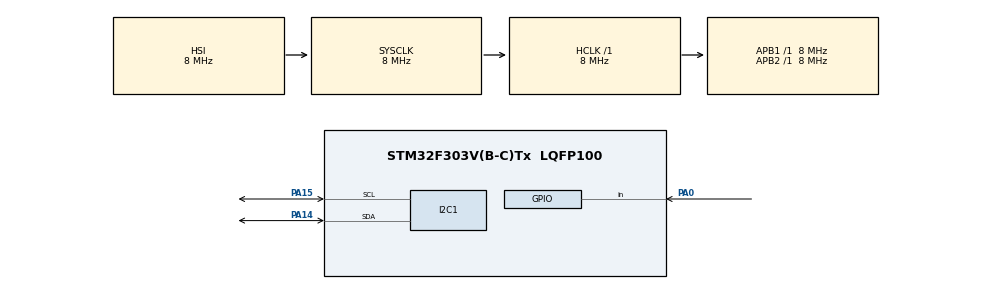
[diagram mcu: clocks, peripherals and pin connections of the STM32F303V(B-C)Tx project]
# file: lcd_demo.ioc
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Dma.I2C1_RX.1.Direction=DMA_PERIPH_TO_MEMORY
Dma.I2C1_RX.1.Instance=DMA1_Channel7
Dma.I2C1_RX.1.MemDataAlignment=DMA_MDATAALIGN_BYTE
Dma.I2C1_RX.1.MemInc=DMA_MINC_ENABLE
Dma.I2C1_RX.1.Mode=DMA_NORMAL
Dma.I2C1_RX.1.PeriphDataAlignment=DMA_PDATAALIGN_BYTE
Dma.I2C1_RX.1.PeriphInc=DMA_PINC_DISABLE
Dma.I2C1_RX.1.Priority=DMA_PRIORITY_LOW
Dma.I2C1_TX.0.Direction=DMA_MEMORY_TO_PERIPH
Dma.I2C1_TX.0.Instance=DMA1_Channel6
Dma.I2C1_TX.0.MemDataAlignment=DMA_MDATAALIGN_BYTE
Dma.I2C1_TX.0.MemInc=DMA_MINC_ENABLE
Dma.I2C1_TX.0.Mode=DMA_NORMAL
Dma.I2C1_TX.0.PeriphDataAlignment=DMA_PDATAALIGN_BYTE
Dma.I2C1_TX.0.PeriphInc=DMA_PINC_DISABLE
Dma.I2C1_TX.0.Priority=DMA_PRIORITY_LOW
Dma.Request0=I2C1_TX
Dma.Request1=I2C1_RX
FREERTOS.INCLUDE_vTaskDelayUntil=1
FREERTOS.Tasks01=defaultTask,0,128,StartDefaultTask,Default,NULL,Dynamic,NULL,NULL
Mcu.Family=STM32F3
Mcu.Name=STM32F303V(B-C)Tx
Mcu.Package=LQFP100
NVIC.DMA1_Channel6_IRQn=true\:5\:0\:false\:false\:true\:true\:false\:true
NVIC.DMA1_Channel7_IRQn=true\:5\:0\:false\:false\:true\:true\:false\:true
NVIC.I2C1_ER_IRQn=true\:5\:0\:false\:false\:true\:true\:true\:true
NVIC.I2C1_EV_IRQn=true\:5\:0\:false\:false\:true\:true\:true\:true
NVIC.PriorityGroup=NVIC_PRIORITYGROUP_4
PA0.Signal=GPIO_Input
PA14.Mode=I2C
PA14.Signal=I2C1_SDA
PA15.Mode=I2C
PA15.Signal=I2C1_SCL
ProjectManager.HeapSize=0x200
ProjectManager.StackSize=0x400
ProjectManager.TargetToolchain=STM32CubeIDE
RCC.AHBFreq_Value=8000000
RCC.APB1Freq_Value=8000000
RCC.APB2Freq_Value=8000000
RCC.CortexFreq_Value=8000000
RCC.HSE_VALUE=8000000
RCC.HSI_VALUE=8000000
RCC.LSE_VALUE=32768
RCC.SYSCLKFreq_VALUE=8000000
VP_FREERTOS_VS_CMSIS_V1.Mode=CMSIS_V1
board=custom

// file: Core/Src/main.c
/* USER CODE BEGIN Header */
/**
  ******************************************************************************
  * @file           : main.c
  * @brief          : Main program body
  ******************************************************************************
  * @attention
  *
  * Copyright (c) 2022 STMicroelectronics.
  * All rights reserved.
  *
  * This software is licensed under terms that can be found in the LICENSE file
  * in the root directory of this software component.
  * If no LICENSE file comes with this software, it is provided AS-IS.
  *
  ******************************************************************************
  */
/* USER CODE END Header */
#include "main.h"
#include "cmsis_os.h"

/* USER CODE BEGIN Includes */
#include "lcd_hd44780_i2c.h"
#include <stdio.h>
#include <string.h>
/* USER CODE END Includes */

I2C_HandleTypeDef hi2c1;
DMA_HandleTypeDef hdma_i2c1_tx;
DMA_HandleTypeDef hdma_i2c1_rx;

osThreadId defaultTaskHandle;

void SystemClock_Config(void);
static void MX_GPIO_Init(void);
static void MX_I2C1_Init(void);
static void MX_DMA_Init(void);
void StartDefaultTask(void const * argument);

int main(void)
{
  /* USER CODE BEGIN 1 */
	lcdInit(&hi2c1, 0x4E, 2, 16);       			      // init lcd (i2c reference, LCD address, lines, rows)
	lcdAutoscrollOff();								              // turn off autoscroll
	lcdBacklightOn();								                // turn on backlight
	lcdDisplayClear();                  			      // clear the screen

  /* USER CODE END 1 */

  /* MCU Configuration--------------------------------------------------------*/

  /* Reset of all peripherals, Initializes the Flash interface and the Systick. */
  HAL_Init();

  /* Configure the system clock */
  SystemClock_Config();

  /* Initialize all configured peripherals */
  MX_GPIO_Init();
  MX_I2C1_Init();
  MX_DMA_Init();

  /* Create the thread(s) */
  /* definition and creation of defaultTask */
  osThreadDef(defaultTask, StartDefaultTask, osPriorityNormal, 0, 128);
  defaultTaskHandle = osThreadCreate(osThread(defaultTask), NULL);

  /* Start scheduler */
  osKernelStart();

  /* We should never get here as control is now taken by the scheduler */
  /* Infinite loop */
  /* USER CODE BEGIN WHILE */
  while (1)
  {
    /* USER CODE END WHILE*/
	lcdSetCursorPosition(2, 0);         			      // set the cursor
	lcdPrintStr((uint8_t*)"welcome AERO!", 13);   	// print
	lcdSetCursorPosition(2, 1);         			      // next line
	lcdPrintStr((uint8_t*)"booting up...", 13);   	// print

	HAL_Delay(3000);
	lcdDisplayClear();

  }
}

void SystemClock_Config(void)
{
  RCC_OscInitTypeDef RCC_OscInitStruct = {0};
  RCC_ClkInitTypeDef RCC_ClkInitStruct = {0};
  RCC_PeriphCLKInitTypeDef PeriphClkInit = {0};

  /** Initializes the RCC Oscillators according to the specified parameters
  * in the RCC_OscInitTypeDef structure.
  */
  RCC_OscInitStruct.OscillatorType = RCC_OSCILLATORTYPE_HSI;
  RCC_OscInitStruct.HSIState = RCC_HSI_ON;
  RCC_OscInitStruct.HSICalibrationValue = RCC_HSICALIBRATION_DEFAULT;
  RCC_OscInitStruct.PLL.PLLState = RCC_PLL_NONE;
  if (HAL_RCC_OscConfig(&RCC_OscInitStruct) != HAL_OK)
  {
    Error_Handler();
  }
  /** Initializes the CPU, AHB and APB buses clocks
  */
  RCC_ClkInitStruct.ClockType = RCC_CLOCKTYPE_HCLK|RCC_CLOCKTYPE_SYSCLK
                              |RCC_CLOCKTYPE_PCLK1|RCC_CLOCKTYPE_PCLK2;
  RCC_ClkInitStruct.SYSCLKSource = RCC_SYSCLKSOURCE_HSI;
  RCC_ClkInitStruct.AHBCLKDivider = RCC_SYSCLK_DIV1;
  RCC_ClkInitStruct.APB1CLKDivider = RCC_HCLK_DIV1;
  RCC_ClkInitStruct.APB2CLKDivider = RCC_HCLK_DIV1;

  if (HAL_RCC_ClockConfig(&RCC_ClkInitStruct, FLASH_LATENCY_0) != HAL_OK)
  {
    Error_Handler();
  }
  PeriphClkInit.PeriphClockSelection = RCC_PERIPHCLK_I2C1;
  PeriphClkInit.I2c1ClockSelection = RCC_I2C1CLKSOURCE_HSI;
  if (HAL_RCCEx_PeriphCLKConfig(&PeriphClkInit) != HAL_OK)
  {
    Error_Handler();
  }
}

static void MX_I2C1_Init(void)
{

  hi2c1.Instance = I2C1;
  hi2c1.Init.Timing = 0x2000090E;
  hi2c1.Init.OwnAddress1 = 0;
  hi2c1.Init.AddressingMode = I2C_ADDRESSINGMODE_7BIT;
  hi2c1.Init.DualAddressMode = I2C_DUALADDRESS_DISABLE;
  hi2c1.Init.OwnAddress2 = 0;
  hi2c1.Init.OwnAddress2Masks = I2C_OA2_NOMASK;
  hi2c1.Init.GeneralCallMode = I2C_GENERALCALL_DISABLE;
  hi2c1.Init.NoStretchMode = I2C_NOSTRETCH_DISABLE;
  if (HAL_I2C_Init(&hi2c1) != HAL_OK)
  {
    Error_Handler();
  }
  /** Configure Analogue filter
  */
  if (HAL_I2CEx_ConfigAnalogFilter(&hi2c1, I2C_ANALOGFILTER_ENABLE) != HAL_OK)
  {
    Error_Handler();
  }
  /** Configure Digital filter
  */
  if (HAL_I2CEx_ConfigDigitalFilter(&hi2c1, 0) != HAL_OK)
  {
    Error_Handler();
  }

}

static void MX_DMA_Init(void)
{

  /* DMA controller clock enable */
  __HAL_RCC_DMA1_CLK_ENABLE();

  /* DMA interrupt init */
  /* DMA1_Channel6_IRQn interrupt configuration */
  HAL_NVIC_SetPriority(DMA1_Channel6_IRQn, 5, 0);
  HAL_NVIC_EnableIRQ(DMA1_Channel6_IRQn);
  /* DMA1_Channel7_IRQn interrupt configuration */
  HAL_NVIC_SetPriority(DMA1_Channel7_IRQn, 5, 0);
  HAL_NVIC_EnableIRQ(DMA1_Channel7_IRQn);

}

static void MX_GPIO_Init(void)
{
  GPIO_InitTypeDef GPIO_InitStruct = {0};

  /* GPIO Ports Clock Enable */
  __HAL_RCC_GPIOA_CLK_ENABLE();

  /*Configure GPIO pin : PA0 */
  GPIO_InitStruct.Pin = GPIO_PIN_0;
  GPIO_InitStruct.Mode = GPIO_MODE_INPUT;
  GPIO_InitStruct.Pull = GPIO_NOPULL;
  HAL_GPIO_Init(GPIOA, &GPIO_InitStruct);

}

void StartDefaultTask(void const * argument)
{
  for(;;)
  {
    osDelay(1);
  }
}

void Error_Handler(void)
{
  __disable_irq();
  while (1)
  {
  }
}
